# RS1xxxx register map
Vendor: Silicon Lab Inc.; Series: ARMCM4; File version: 1.2
CPU: CM4 r1p0, little endian, MPU, FPU, 6 interrupt priority bits
Registers are 32-bit, read-write, reset 0x0 unless marked. A register's access mark holds for its fields unless they carry their own. Offsets are from the block's base; [hi:lo] are bit positions; lines under a group give offsets from that group; {n}, {i} and the like mark numbered series; 'fields as' and 'values as' point back to an identical list.

## PAD_SELECTION
Base 0x41300000
0x00 MEM_GPIO_ACCESS_CTRL_SET reset 0x20 — Indicates the PAD Configuration Control for GPIO_25-GPIO_30.
  [5] SZP_MCUHP_GPIO_CTRL2 — Write 1 enables SZP to configure GPIO_25 TO GPIO_30
    1=ENABLE_SZP_CONFIG_GPIO_25_TO_30 (Writing 1 to this ensables SZP to configure the GPIO_25 to GPIO_30); 0=No_Effect
0x04 MEM_GPIO_ACCESS_CTRL_CLEAR reset 0x20 — Indicates the PAD Configuration Control for GPIO_25-GPIO_30.
  [5] SZP_MCUHP_GPIO_CTRL2 — Write 1 enables MCUHP to configure GPIO_25 TO GPIO_30
    1=ENABLE_MCUHP_CONFIG_GPIO_25_TO_30 (Writing 1 to this ensables SZP to configure the GPIO_25 to GPIO_30); 0=No_Effect
0x610 MCUHP_PAD_SELECTION — Indicates the PAD Configuration Control for GPIO_0 to GPIO_57 pads except for GPIO_25-GPIO_30.
  [21:0] SZP_MCUHP_GPIO_CTRL1_0_to_21 — PAD Configuration Controls between NWP and MCU HP.
    1=WRITE_1 (Writing 1 to a particular bit enables the MCU HP to configure the corresponding PADs); 0=WRITE_0 (Writing 0 to a particular bit enables the SZP/NWP to configure the corresponding PADs)
0x618 MCUHP_PAD_SELECTION_1 — Indicates the PAD Configuration Control for ULP_GPIO_0 to ULP_GPIO_11 pads when used as SoC GPIO function for SoC_GPIO_64 to SoC_GPIO_75
  [11:0] SZP_MCUHP_GPIO_CTRL1_22_to_33 — PAD Configuration Controls between NWP and MCU HP.
    values as MCUHP_PAD_SELECTION.SZP_MCUHP_GPIO_CTRL1_0_to_21

## PAD_CONFIGURATIONs — PAD Configuration registers
Base 0x46006000
{0x0+4i} MCU_HP_GPIO_PAD_CONFIGs[{i}] (i=0..63) group — PAD Configuration Register for GPIO_n; n = 0,1,2, ..... 63
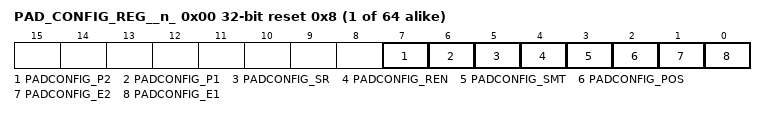
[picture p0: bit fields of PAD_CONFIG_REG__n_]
  0x00 PAD_CONFIG_REG__n_ reset 0x8 (reset mask 0x8) — PAD Configuration for _n_
    [7] PADCONFIG_P2 — P[2,1]–Driver disabled state control,0-Hi-Z/1-Pull-up/2-Pull-down/3-Repeater
    [6] PADCONFIG_P1 — P[2,1]–Driver disabled state control,0-Hi-Z/1-Pull-up/2-Pull-down/3-Repeater
    [5] PADCONFIG_SR — Slew Rate Control
    [4] PADCONFIG_REN — Active high receiver enable
    [3] PADCONFIG_SMT — Active high Schmitt trigger (Hysteresis) select; SMT=0 – No hysteres
    [2] PADCONFIG_POS — Power-on-Start enable;
    [1] PADCONFIG_E2 — E[2,1] – Drive strength selector, 0-2 mA / 1-4 mA / 2-8 mA / 3-12 ma
    [0] PADCONFIG_E1 — E[2,1] – Drive strength selector, 0-2 mA / 1-4 mA / 2-8 mA / 3-12 ma

## Secure_Storage
Base 0x24048500
{0x80+4i} MCU_STORAGE_REGn[{i}] (i=0..7) group — MCU storage registers (0-7)
  0x00 MCU_STORAGE_REG_n_ reset not defined — MCU STorage register _n_
    [31:0] MCU_STORAGE_WORD__n_ — This register Can be used to storing 32bits of Data.
0x200 MCU_STORAGE_WRITE_KEY reset not defined — Programming the key will enable or disable access to program MCU storage register
  [31:0] MCU_STORAGE_KEY — By default the Access to MCU storage Register is enabled

## HF_PLL_Clocks — High frequency PLL clocks registers
Base 0x46180000
0x04 PLL_REF_CLK_CONFIG_REG reset not defined — Reference Clock Configuration Register
  [15:14] REF_CLK_SEL — Specified the input reference clock for the PLL's
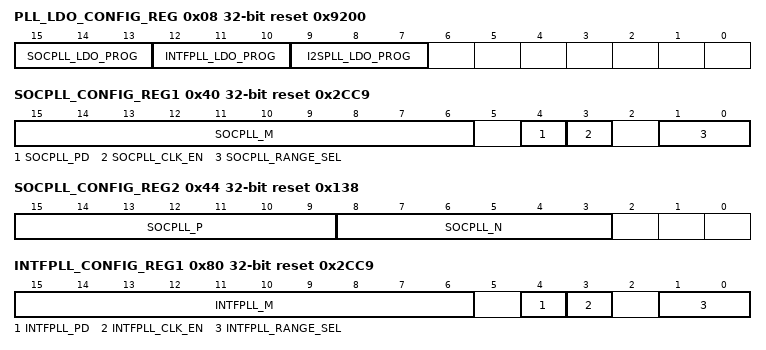
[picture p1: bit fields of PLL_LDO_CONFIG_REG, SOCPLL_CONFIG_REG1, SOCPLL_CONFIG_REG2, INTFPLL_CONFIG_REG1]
0x08 PLL_LDO_CONFIG_REG reset 0x9200 — LDO Configuration Register
  [15:13] SOCPLL_LDO_PROG — Specified the configuration of SoC-PLL LDO output voltage
  [12:10] INTFPLL_LDO_PROG — Specified the configuration of Interface-PLL LDO output voltage
  [9:7] I2SPLL_LDO_PROG — Specified the configuration of I2S-PLL LDO output voltage
0x40 SOCPLL_CONFIG_REG1 reset 0x2CC9 — SoC-PLL Configuration Register1
  [15:6] SOCPLL_M — Specifies the SoC-PLL Multiplication Factor.
  [4] SOCPLL_PD — Writing 1 disables power to SOC-PLL,1 enables it
  [3] SOCPLL_CLK_EN — Writing 1 enables SOC-PLL output clock ,0 disables it
  [1:0] SOCPLL_RANGE_SEL — Specifies the range for the Output frequency.
0x44 SOCPLL_CONFIG_REG2 reset 0x138 — SoC-PLL Configuration Register2
  [15:9] SOCPLL_P — Specifies the SoC-PLL Output Division Factor
  [8:3] SOCPLL_N — Specifies the SoC-PLL Input Division Factor
0x48 SOCPLL_CONFIG_REG3 — SoC-PLL Configuration Register3
  [15:2] SOCPLL_FCW — Specifies the SoC-PLL Fractional Frequency Control Word
0x70 SOCPLL_STATUS_REG ro — SoC-PLL Status Register
  [15] SOCPLL_LOCK — Indicates the SoC-PLL Status 1 locked, 0 notlocked
0x80 INTFPLL_CONFIG_REG1 reset 0x2CC9 — INTF-PLL Configuration Register1
  [15:6] INTFPLL_M — Specifies the INTF-PLL Multiplication Factor.
  [4] INTFPLL_PD — Writing 1 disables power to INTF-PLL,1 enables it
  [3] INTFPLL_CLK_EN — Writing 1 enables SOC-PLL output clock ,0 disables it
  [1:0] INTFPLL_RANGE_SEL — Specifies the range for the Output frequency.
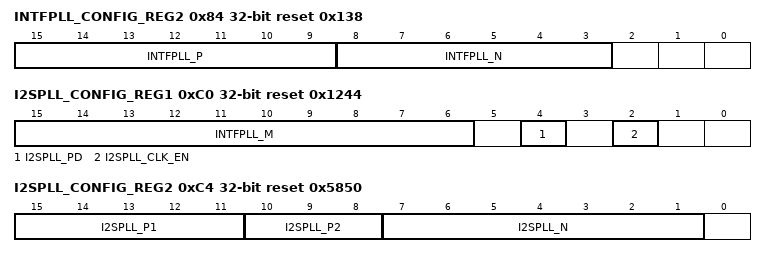
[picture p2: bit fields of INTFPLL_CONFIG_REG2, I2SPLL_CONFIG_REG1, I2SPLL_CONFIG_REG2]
0x84 INTFPLL_CONFIG_REG2 reset 0x138 — INTF-PLL Configuration Register2
  [15:9] INTFPLL_P — Specifies the SoC-PLL Output Division Factor
  [8:3] INTFPLL_N — Specifies the INTF-PLL Input Division Factor
0x88 INTFPLL_CONFIG_REG3 — INTF-PLL Configuration Register3
  [15:2] INTFPLL_FCW — Specifies the INTF-PLL Fractional Frequency Control Word
0xA0 INTFPLL_STATUS_REG ro — INTF-PLL Status Register
  [15] INTFPLL_LOCK — Indicates the INTF-PLL Status 1 locked, 0 notlocked
0xC0 I2SPLL_CONFIG_REG1 reset 0x1244 — I2S-PLL Configuration Register1
  [15:6] INTFPLL_M — Specifies the I2S-PLL Multiplication Factor.
  [4] I2SPLL_PD — Writing 1 disables power to I2S-PLL,1 enables it
  [2] I2SPLL_CLK_EN — Writing 1 enables I2S-PLL output clock ,0 disables it
0xC4 I2SPLL_CONFIG_REG2 reset 0x5850 — I2S-PLL Configuration Register2
  [15:11] I2SPLL_P1 — Specifies the I2S-PLL Output Division Factor
  [10:8] I2SPLL_P2 — Specifies the I2S-PLL Output Division Factor
  [7:1] I2SPLL_N — Specifies the I2S-PLL Input Division Factor
0xC8 I2SPLL_CONFIG_REG3 reset 0xBA60 — I2S-PLL Configuration Register3
  [15:2] I2SPLL_FCW — Specifies the I2SF-PLL Fractional Frequency Control Word
0xF0 I2SPLL_STATUS_REG ro — I2S-PLL Status Register
  [15] I2SPLL_LOCK — Indicates the I2S-PLL Status 1 locked, 0 notlocked
